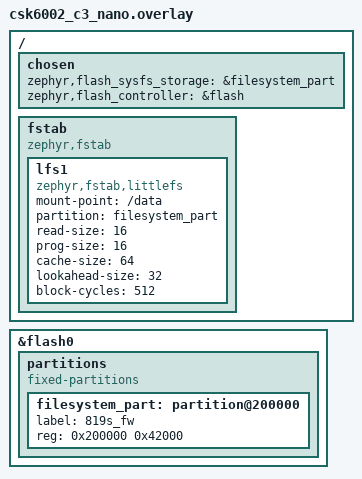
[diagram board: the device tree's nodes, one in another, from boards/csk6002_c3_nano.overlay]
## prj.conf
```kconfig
CONFIG_GPIO=y
CONFIG_SPI=y
CONFIG_WIFI=y
CONFIG_CSK_WIFI_STATION=y
CONFIG_ESP_HOSTED=y
CONFIG_NET_L2_ETHERNET=y

CONFIG_NEWLIB_LIBC=y

CONFIG_NETWORKING=y
CONFIG_NET_DHCPV4=y
CONFIG_NET_IPV4=y
CONFIG_NET_SOCKETS=y
CONFIG_NET_SOCKETS_POSIX_NAMES=y

CONFIG_NET_MGMT=y
CONFIG_NET_MGMT_EVENT=y
CONFIG_NET_MGMT_EVENT_STACK_SIZE=4096

CONFIG_NET_RX_STACK_SIZE=2048
CONFIG_NET_TX_STACK_SIZE=2048
CONFIG_NET_PKT_RX_COUNT=16
CONFIG_NET_PKT_TX_COUNT=16
CONFIG_NET_BUF_RX_COUNT=64
CONFIG_NET_BUF_TX_COUNT=64
CONFIG_NET_CONTEXT_NET_PKT_POOL=y

CONFIG_HEAP_MEM_POOL_SIZE=122880
CONFIG_MAIN_STACK_SIZE=4096
CONFIG_TEST_RANDOM_GENERATOR=y
CONFIG_INIT_STACKS=y
CONFIG_LOG=y
CONFIG_THREAD_NAME=y
CONFIG_DEBUG_THREAD_INFO=y
```

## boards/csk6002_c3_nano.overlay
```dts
/*
 * Copyright (c) 2021 listenai Intelligent Technology (anhui) Co., Ltd.
 *
 * SPDX-License-Identifier: Apache-2.0
 */
/delete-node/ &storage_partition;

/ {
	chosen {
		/*
		 * shared memory reserved for the inter-processor communication
		 */
		zephyr,flash_sysfs_storage = &filesystem_part;
		zephyr,flash_controller = &flash;
	};
	
	fstab {
		compatible = "zephyr,fstab";
		lfs1: lfs1 {
			compatible = "zephyr,fstab,littlefs";
			mount-point = "/data";
			partition = <&filesystem_part>;
			read-size = <16>;
			prog-size = <16>;
			cache-size = <64>;
			lookahead-size = <32>;
			block-cycles = <512>;
		};
	};

};

 
&flash0 {
	partitions {
		compatible = "fixed-partitions";
		#address-cells = <1>;
		#size-cells = <1>;
		filesystem_part: partition@200000 {
			label = "819s_fw";
			reg = <0x200000 0x42000>;
		};
	};
};
```

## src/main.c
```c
/*
 * SPDX-License-Identifier: Apache-2.0
 */

#include <stdlib.h>
#include <sys/printk.h>
#include <sys/sys_heap.h>

#include <net/net_if.h>
#include <net/net_core.h>
#include <net/net_context.h>
#include <net/net_mgmt.h>


#include "csk6001/csk_wifi.h"

static csk_wifi_event_cb_t wifi_event_cb;
static struct net_mgmt_event_callback dhcp_cb;
static void handler_cb(struct net_mgmt_event_callback *cb, uint32_t mgmt_event, struct net_if *iface)
{
    if (mgmt_event != NET_EVENT_IPV4_DHCP_BOUND) {
        return;
    }

    char buf[NET_IPV4_ADDR_LEN];

    printk("Your address: %s\n", net_addr_ntop(AF_INET, &iface->config.dhcpv4.requested_ip, buf, sizeof(buf)));
    printk("Lease time: %u seconds\n", iface->config.dhcpv4.lease_time);
    printk("Subnet: %s\n", net_addr_ntop(AF_INET, &iface->config.ip.ipv4->netmask, buf, sizeof(buf)));
    printk("Router: %s\n", net_addr_ntop(AF_INET, &iface->config.ip.ipv4->gw, buf, sizeof(buf)));
}

static void wifi_event_handler(csk_wifi_event_t events, void *event_data, uint32_t data_len, void *arg)
{
    if (events & CSK_WIFI_EVT_STA_CONNECTED) {
        printk("[WiFi sta] connected\n");
    } else if (events & CSK_WIFI_EVT_STA_DISCONNECTED) {
        printk("[WiFi sta] disconnected\n");
    } else {
        abort();
    }
}

void main(void)
{
    csk_wifi_init();
    wifi_event_cb.handler = &wifi_event_handler;
    wifi_event_cb.events = CSK_WIFI_EVT_STA_CONNECTED | CSK_WIFI_EVT_STA_DISCONNECTED;
    wifi_event_cb.arg = NULL;
    csk_wifi_add_callback(&wifi_event_cb);

    csk_wifi_sta_config_t sta_config = {
        .ssid = CONFIG_EXAMPLE_WIFI_SSID,
        .pwd = CONFIG_EXAMPLE_WIFI_PASSWORD,
        .encryption_mode = CSK_WIFI_AUTH_WPA2_PSK
    };

    int retry_count = 0;
    csk_wifi_result_t wifi_result;
    do {
        printk("connecting to wifi: %s ...\n", sta_config.ssid);
        int ret = csk_wifi_sta_connect(&sta_config, &wifi_result, K_FOREVER);
        if (ret == 0) {
            break;
        } else {
            if (wifi_result == CSK_WIFI_ERR_STA_FAILED) {
                retry_count++;
                printk("retry to connecting wifi ... %d\n", retry_count);
            } else {
                printk("AP not found or invalid password\n");
                return;
            }
        }
    } while (retry_count < 10);
    printk("--------------------------Current AP info-------------------------------\n");
    printk("ssid: %s  pwd: %s  bssid: %s  channel: %d  rssi: %d\n",
        sta_config.ssid, sta_config.pwd, sta_config.bssid, sta_config.channel,
        sta_config.rssi);
    printk("------------------------------------------------------------------------\n");
    net_mgmt_init_event_callback(&dhcp_cb, handler_cb, NET_EVENT_IPV4_DHCP_BOUND);
    net_mgmt_add_event_callback(&dhcp_cb);
    struct net_if *iface = net_if_get_default();
    if (!iface) {
        printk("wifi interface not available");
        return;
    }
    net_dhcpv4_start(iface);
}
```
